# StarFive VisionFive 2 v1.3b register map
File version: 0.1
Registers are 32-bit, read-write, no defined reset value unless marked. A register's access mark holds for its fields unless they carry their own. Offsets are from the block's base; [hi:lo] are bit positions; {n}, {i} and the like mark numbered series.

## starfive_jh7110_sys_pinctrl_0 (part 1 of 3) — From starfive,jh7110-sys-pinctrl, peripheral generator
Base 0x13040000
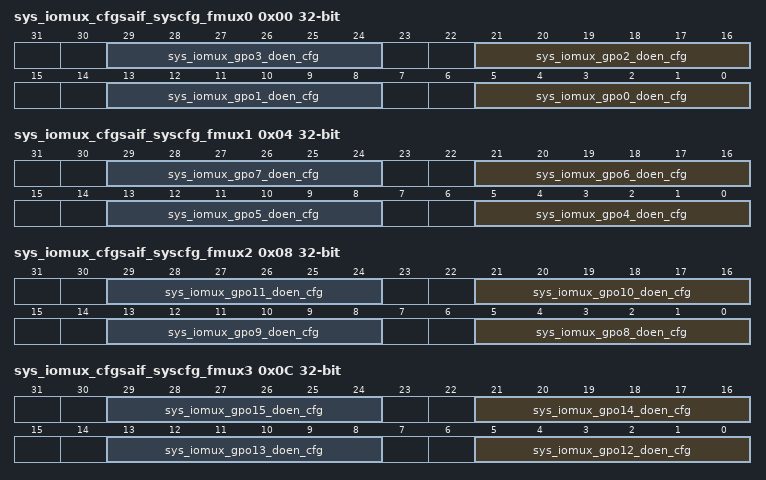
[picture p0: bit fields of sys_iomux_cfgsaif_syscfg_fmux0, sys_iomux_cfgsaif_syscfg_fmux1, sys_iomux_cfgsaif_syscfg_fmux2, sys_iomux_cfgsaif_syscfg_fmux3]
0x00 sys_iomux_cfgsaif_syscfg_fmux0
  [8n+5:8n] sys_iomux_gpo{n}_doen_cfg (n=0..3) — The selected OEN signal for GPIO{n}. The register value indicates the selected GPIO (Output Enable) OEN index from GPIO OEN list 0-49. See Table 2-41: GPIO OEN List for SYS_IOMUX (on page 97) for more information.
0x04 sys_iomux_cfgsaif_syscfg_fmux1
  [8n-27:8n-32] sys_iomux_gpo{n}_doen_cfg (n=4..7) — The selected OEN signal for GPIO{n}. The register value indicates the selected GPIO (Output Enable) OEN index from GPIO OEN list 0-49. See Table 2-41: GPIO OEN List for SYS_IOMUX (on page 97) for more information.
0x08 sys_iomux_cfgsaif_syscfg_fmux2
  [8n-59:8n-64] sys_iomux_gpo{n}_doen_cfg (n=8..11) — The selected OEN signal for GPIO{n}. The register value indicates the selected GPIO (Output Enable) OEN index from GPIO OEN list 0-49. See Table 2-41: GPIO OEN List for SYS_IOMUX (on page 97) for more information.
0x0C sys_iomux_cfgsaif_syscfg_fmux3
  [8n-91:8n-96] sys_iomux_gpo{n}_doen_cfg (n=12..15) — The selected OEN signal for GPIO{n}. The register value indicates the selected GPIO (Output Enable) OEN index from GPIO OEN list 0-49. See Table 2-41: GPIO OEN List for SYS_IOMUX (on page 97) for more information.
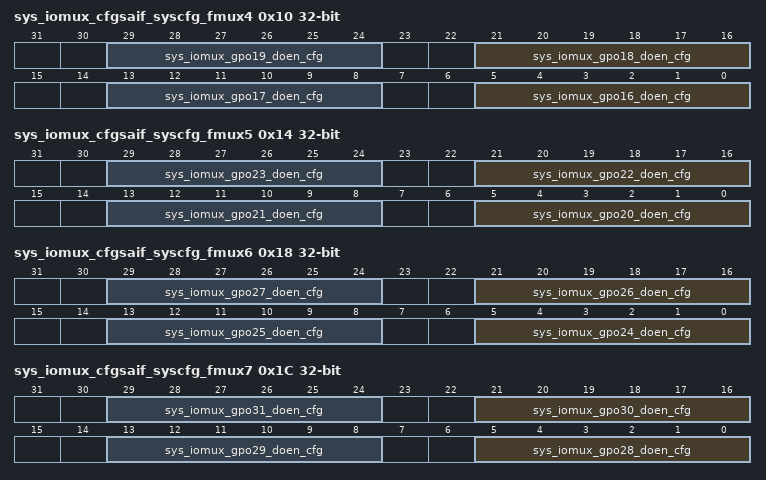
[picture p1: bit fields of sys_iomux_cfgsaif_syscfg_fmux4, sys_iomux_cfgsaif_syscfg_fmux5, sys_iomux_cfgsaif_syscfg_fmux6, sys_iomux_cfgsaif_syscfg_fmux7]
0x10 sys_iomux_cfgsaif_syscfg_fmux4
  [8n-123:8n-128] sys_iomux_gpo{n}_doen_cfg (n=16..19) — The selected OEN signal for GPIO{n}. The register value indicates the selected GPIO (Output Enable) OEN index from GPIO OEN list 0-49. See Table 2-41: GPIO OEN List for SYS_IOMUX (on page 97) for more information.
0x14 sys_iomux_cfgsaif_syscfg_fmux5
  [8n-155:8n-160] sys_iomux_gpo{n}_doen_cfg (n=20..23) — The selected OEN signal for GPIO{n}. The register value indicates the selected GPIO (Output Enable) OEN index from GPIO OEN list 0-49. See Table 2-41: GPIO OEN List for SYS_IOMUX (on page 97) for more information.
0x18 sys_iomux_cfgsaif_syscfg_fmux6
  [8n-187:8n-192] sys_iomux_gpo{n}_doen_cfg (n=24..27) — The selected OEN signal for GPIO{n}. The register value indicates the selected GPIO (Output Enable) OEN index from GPIO OEN list 0-49. See Table 2-41: GPIO OEN List for SYS_IOMUX (on page 97) for more information.
0x1C sys_iomux_cfgsaif_syscfg_fmux7
  [8n-219:8n-224] sys_iomux_gpo{n}_doen_cfg (n=28..31) — The selected OEN signal for GPIO{n}. The register value indicates the selected GPIO (Output Enable) OEN index from GPIO OEN list 0-49. See Table 2-41: GPIO OEN List for SYS_IOMUX (on page 97) for more information.
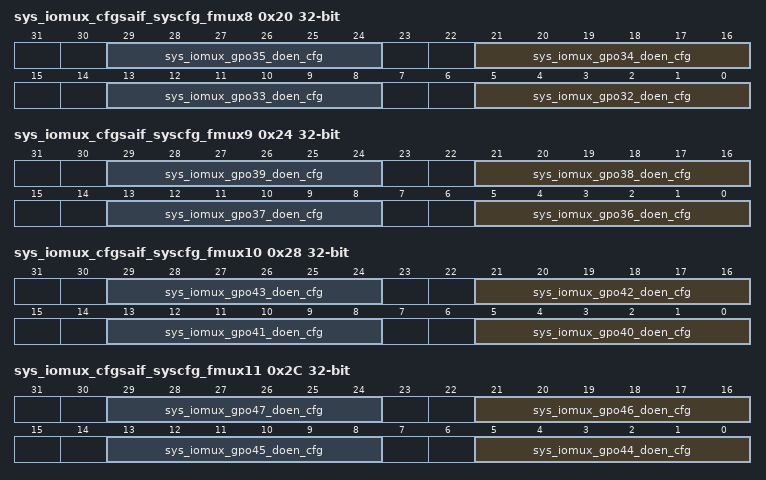
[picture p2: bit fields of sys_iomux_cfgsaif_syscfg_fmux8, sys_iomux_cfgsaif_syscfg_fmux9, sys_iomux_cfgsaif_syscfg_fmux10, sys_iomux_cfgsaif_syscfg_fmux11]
0x20 sys_iomux_cfgsaif_syscfg_fmux8
  [8n-251:8n-256] sys_iomux_gpo{n}_doen_cfg (n=32..35) — The selected OEN signal for GPIO{n}. The register value indicates the selected GPIO (Output Enable) OEN index from GPIO OEN list 0-49. See Table 2-41: GPIO OEN List for SYS_IOMUX (on page 97) for more information.
0x24 sys_iomux_cfgsaif_syscfg_fmux9
  [8n-283:8n-288] sys_iomux_gpo{n}_doen_cfg (n=36..39) — The selected OEN signal for GPIO{n}. The register value indicates the selected GPIO (Output Enable) OEN index from GPIO OEN list 0-49. See Table 2-41: GPIO OEN List for SYS_IOMUX (on page 97) for more information.
0x28 sys_iomux_cfgsaif_syscfg_fmux10
  [8n-315:8n-320] sys_iomux_gpo{n}_doen_cfg (n=40..43) — The selected OEN signal for GPIO{n}. The register value indicates the selected GPIO (Output Enable) OEN index from GPIO OEN list 0-49. See Table 2-41: GPIO OEN List for SYS_IOMUX (on page 97) for more information.
0x2C sys_iomux_cfgsaif_syscfg_fmux11
  [8n-347:8n-352] sys_iomux_gpo{n}_doen_cfg (n=44..47) — The selected OEN signal for GPIO{n}. The register value indicates the selected GPIO (Output Enable) OEN index from GPIO OEN list 0-49. See Table 2-41: GPIO OEN List for SYS_IOMUX (on page 97) for more information.
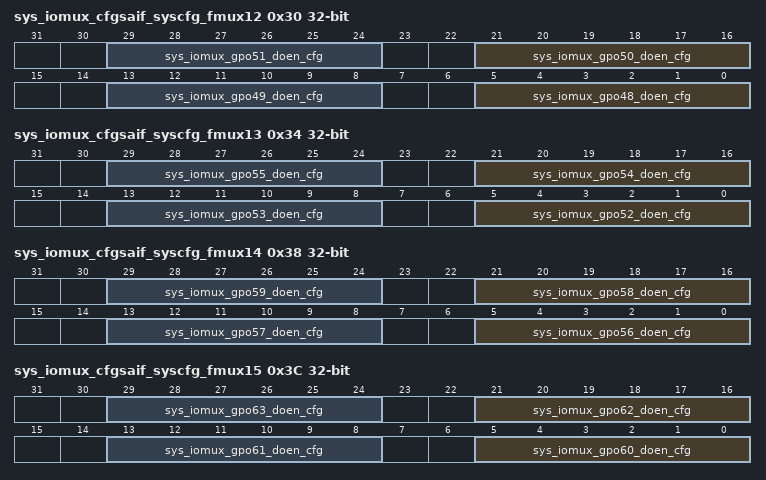
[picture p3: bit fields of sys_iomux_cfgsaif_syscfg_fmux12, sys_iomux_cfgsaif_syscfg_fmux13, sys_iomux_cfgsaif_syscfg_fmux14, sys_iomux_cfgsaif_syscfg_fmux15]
0x30 sys_iomux_cfgsaif_syscfg_fmux12
  [8n-379:8n-384] sys_iomux_gpo{n}_doen_cfg (n=48..51) — The selected OEN signal for GPIO{n}. The register value indicates the selected GPIO (Output Enable) OEN index from GPIO OEN list 0-49. See Table 2-41: GPIO OEN List for SYS_IOMUX (on page 97) for more information.
0x34 sys_iomux_cfgsaif_syscfg_fmux13
  [8n-411:8n-416] sys_iomux_gpo{n}_doen_cfg (n=52..55) — The selected OEN signal for GPIO{n}. The register value indicates the selected GPIO (Output Enable) OEN index from GPIO OEN list 0-49. See Table 2-41: GPIO OEN List for SYS_IOMUX (on page 97) for more information.
0x38 sys_iomux_cfgsaif_syscfg_fmux14
  [8n-443:8n-448] sys_iomux_gpo{n}_doen_cfg (n=56..59) — The selected OEN signal for GPIO{n}. The register value indicates the selected GPIO (Output Enable) OEN index from GPIO OEN list 0-49. See Table 2-41: GPIO OEN List for SYS_IOMUX (on page 97) for more information.
0x3C sys_iomux_cfgsaif_syscfg_fmux15
  [8n-475:8n-480] sys_iomux_gpo{n}_doen_cfg (n=60..63) — The selected OEN signal for GPIO{n}. The register value indicates the selected GPIO (Output Enable) OEN index from GPIO OEN list 0-49. See Table 2-41: GPIO OEN List for SYS_IOMUX (on page 97) for more information.
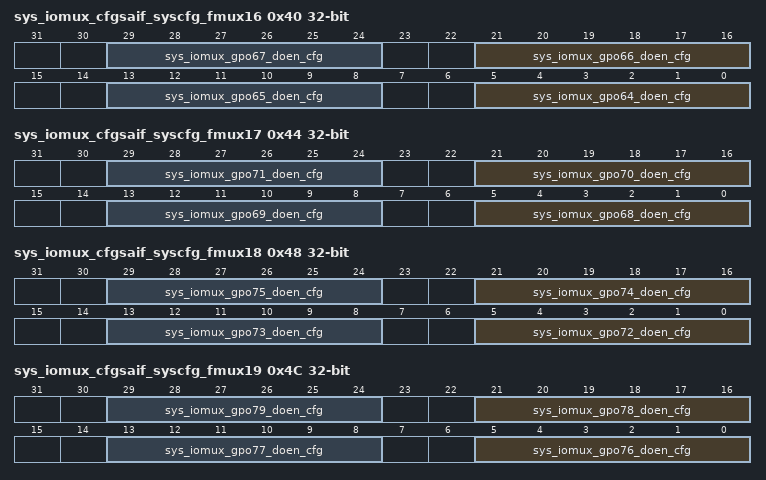
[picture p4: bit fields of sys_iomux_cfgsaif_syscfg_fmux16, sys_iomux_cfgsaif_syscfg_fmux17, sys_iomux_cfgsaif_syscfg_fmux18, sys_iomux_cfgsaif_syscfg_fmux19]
0x40 sys_iomux_cfgsaif_syscfg_fmux16
  [8n-507:8n-512] sys_iomux_gpo{n}_doen_cfg (n=64..67) — The selected OEN signal for GPIO{n}. The register value indicates the selected GPIO (Output Enable) OEN index from GPIO OEN list 0-49. See Table 2-41: GPIO OEN List for SYS_IOMUX (on page 97) for more information.
0x44 sys_iomux_cfgsaif_syscfg_fmux17
  [8n-539:8n-544] sys_iomux_gpo{n}_doen_cfg (n=68..71) — The selected OEN signal for GPIO{n}. The register value indicates the selected GPIO (Output Enable) OEN index from GPIO OEN list 0-49. See Table 2-41: GPIO OEN List for SYS_IOMUX (on page 97) for more information.
0x48 sys_iomux_cfgsaif_syscfg_fmux18
  [8n-571:8n-576] sys_iomux_gpo{n}_doen_cfg (n=72..75) — The selected OEN signal for GPIO{n}. The register value indicates the selected GPIO (Output Enable) OEN index from GPIO OEN list 0-49. See Table 2-41: GPIO OEN List for SYS_IOMUX (on page 97) for more information.
0x4C sys_iomux_cfgsaif_syscfg_fmux19
  [8n-603:8n-608] sys_iomux_gpo{n}_doen_cfg (n=76..79) — The selected OEN signal for GPIO{n}. The register value indicates the selected GPIO (Output Enable) OEN index from GPIO OEN list 0-49. See Table 2-41: GPIO OEN List for SYS_IOMUX (on page 97) for more information.
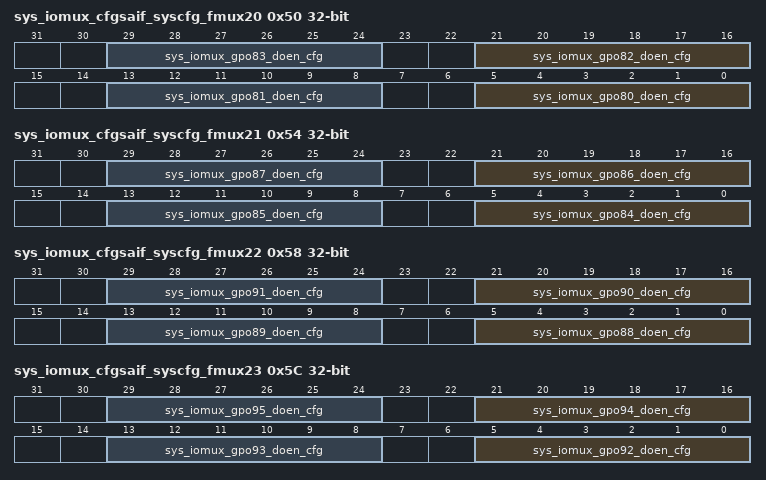
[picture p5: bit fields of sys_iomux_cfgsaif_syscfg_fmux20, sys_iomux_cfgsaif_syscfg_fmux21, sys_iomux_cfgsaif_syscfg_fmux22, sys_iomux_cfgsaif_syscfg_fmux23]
0x50 sys_iomux_cfgsaif_syscfg_fmux20
  [8n-635:8n-640] sys_iomux_gpo{n}_doen_cfg (n=80..83) — The selected OEN signal for GPIO{n}. The register value indicates the selected GPIO (Output Enable) OEN index from GPIO OEN list 0-49. See Table 2-41: GPIO OEN List for SYS_IOMUX (on page 97) for more information.
0x54 sys_iomux_cfgsaif_syscfg_fmux21
  [8n-667:8n-672] sys_iomux_gpo{n}_doen_cfg (n=84..87) — The selected OEN signal for GPIO{n}. The register value indicates the selected GPIO (Output Enable) OEN index from GPIO OEN list 0-49. See Table 2-41: GPIO OEN List for SYS_IOMUX (on page 97) for more information.
0x58 sys_iomux_cfgsaif_syscfg_fmux22
  [8n-699:8n-704] sys_iomux_gpo{n}_doen_cfg (n=88..91) — The selected OEN signal for GPIO{n}. The register value indicates the selected GPIO (Output Enable) OEN index from GPIO OEN list 0-49. See Table 2-41: GPIO OEN List for SYS_IOMUX (on page 97) for more information.
0x5C sys_iomux_cfgsaif_syscfg_fmux23
  [8n-731:8n-736] sys_iomux_gpo{n}_doen_cfg (n=92..95) — The selected OEN signal for GPIO{n}. The register value indicates the selected GPIO (Output Enable) OEN index from GPIO OEN list 0-49. See Table 2-41: GPIO OEN List for SYS_IOMUX (on page 97) for more information.
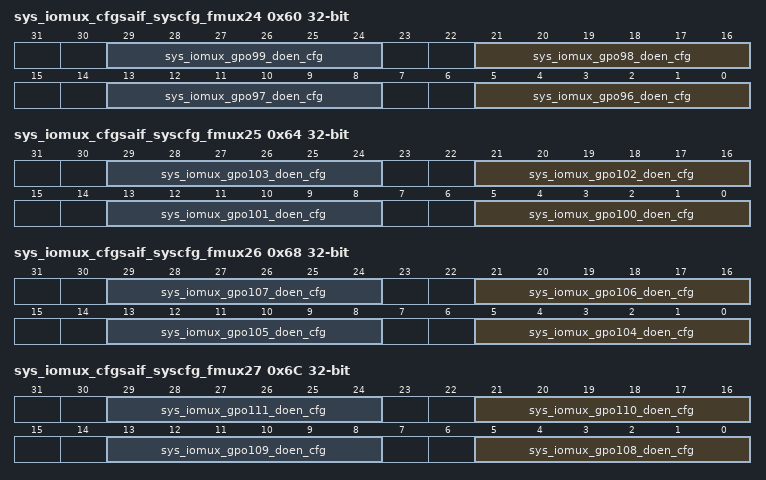
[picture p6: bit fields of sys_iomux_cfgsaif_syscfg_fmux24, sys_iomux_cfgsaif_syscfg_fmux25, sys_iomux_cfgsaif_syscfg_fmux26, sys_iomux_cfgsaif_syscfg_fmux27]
0x60 sys_iomux_cfgsaif_syscfg_fmux24
  [8n-763:8n-768] sys_iomux_gpo{n}_doen_cfg (n=96..99) — The selected OEN signal for GPIO{n}. The register value indicates the selected GPIO (Output Enable) OEN index from GPIO OEN list 0-49. See Table 2-41: GPIO OEN List for SYS_IOMUX (on page 97) for more information.
0x64 sys_iomux_cfgsaif_syscfg_fmux25
  [8n-795:8n-800] sys_iomux_gpo{n}_doen_cfg (n=100..103) — The selected OEN signal for GPIO{n}. The register value indicates the selected GPIO (Output Enable) OEN index from GPIO OEN list 0-49. See Table 2-41: GPIO OEN List for SYS_IOMUX (on page 97) for more information.
0x68 sys_iomux_cfgsaif_syscfg_fmux26
  [8n-827:8n-832] sys_iomux_gpo{n}_doen_cfg (n=104..107) — The selected OEN signal for GPIO{n}. The register value indicates the selected GPIO (Output Enable) OEN index from GPIO OEN list 0-49. See Table 2-41: GPIO OEN List for SYS_IOMUX (on page 97) for more information.
0x6C sys_iomux_cfgsaif_syscfg_fmux27
  [8n-859:8n-864] sys_iomux_gpo{n}_doen_cfg (n=108..111) — The selected OEN signal for GPIO{n}. The register value indicates the selected GPIO (Output Enable) OEN index from GPIO OEN list 0-49. See Table 2-41: GPIO OEN List for SYS_IOMUX (on page 97) for more information.
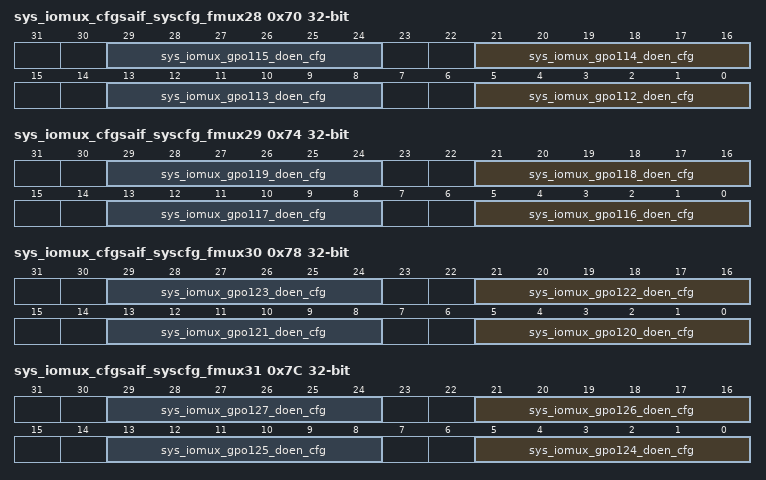
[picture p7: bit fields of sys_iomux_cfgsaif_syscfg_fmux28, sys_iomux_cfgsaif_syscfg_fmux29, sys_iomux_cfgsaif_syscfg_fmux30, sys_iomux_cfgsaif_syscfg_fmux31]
0x70 sys_iomux_cfgsaif_syscfg_fmux28
  [8n-891:8n-896] sys_iomux_gpo{n}_doen_cfg (n=112..115) — The selected OEN signal for GPIO{n}. The register value indicates the selected GPIO (Output Enable) OEN index from GPIO OEN list 0-49. See Table 2-41: GPIO OEN List for SYS_IOMUX (on page 97) for more information.
0x74 sys_iomux_cfgsaif_syscfg_fmux29
  [8n-923:8n-928] sys_iomux_gpo{n}_doen_cfg (n=116..119) — The selected OEN signal for GPIO{n}. The register value indicates the selected GPIO (Output Enable) OEN index from GPIO OEN list 0-49. See Table 2-41: GPIO OEN List for SYS_IOMUX (on page 97) for more information.
0x78 sys_iomux_cfgsaif_syscfg_fmux30
  [8n-955:8n-960] sys_iomux_gpo{n}_doen_cfg (n=120..123) — The selected OEN signal for GPIO{n}. The register value indicates the selected GPIO (Output Enable) OEN index from GPIO OEN list 0-49. See Table 2-41: GPIO OEN List for SYS_IOMUX (on page 97) for more information.
0x7C sys_iomux_cfgsaif_syscfg_fmux31
  [8n-987:8n-992] sys_iomux_gpo{n}_doen_cfg (n=124..127) — The selected OEN signal for GPIO{n}. The register value indicates the selected GPIO (Output Enable) OEN index from GPIO OEN list 0-49. See Table 2-41: GPIO OEN List for SYS_IOMUX (on page 97) for more information.
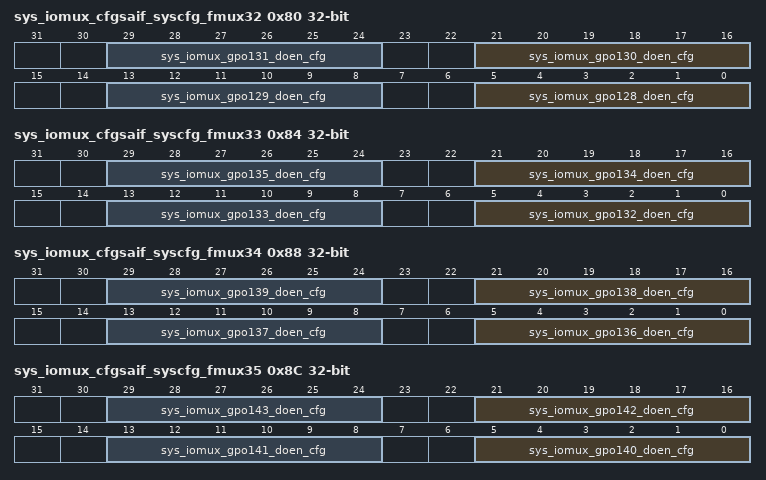
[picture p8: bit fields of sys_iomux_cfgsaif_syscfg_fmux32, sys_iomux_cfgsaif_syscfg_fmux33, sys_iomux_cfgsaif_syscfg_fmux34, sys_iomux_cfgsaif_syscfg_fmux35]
0x80 sys_iomux_cfgsaif_syscfg_fmux32
  [8n-1019:8n-1024] sys_iomux_gpo{n}_doen_cfg (n=128..131) — The selected OEN signal for GPIO{n}. The register value indicates the selected GPIO (Output Enable) OEN index from GPIO OEN list 0-49. See Table 2-41: GPIO OEN List for SYS_IOMUX (on page 97) for more information.
0x84 sys_iomux_cfgsaif_syscfg_fmux33
  [8n-1051:8n-1056] sys_iomux_gpo{n}_doen_cfg (n=132..135) — The selected OEN signal for GPIO{n}. The register value indicates the selected GPIO (Output Enable) OEN index from GPIO OEN list 0-49. See Table 2-41: GPIO OEN List for SYS_IOMUX (on page 97) for more information.
0x88 sys_iomux_cfgsaif_syscfg_fmux34
  [8n-1083:8n-1088] sys_iomux_gpo{n}_doen_cfg (n=136..139) — The selected OEN signal for GPIO{n}. The register value indicates the selected GPIO (Output Enable) OEN index from GPIO OEN list 0-49. See Table 2-41: GPIO OEN List for SYS_IOMUX (on page 97) for more information.
0x8C sys_iomux_cfgsaif_syscfg_fmux35
  [8n-1115:8n-1120] sys_iomux_gpo{n}_doen_cfg (n=140..143) — The selected OEN signal for GPIO{n}. The register value indicates the selected GPIO (Output Enable) OEN index from GPIO OEN list 0-49. See Table 2-41: GPIO OEN List for SYS_IOMUX (on page 97) for more information.
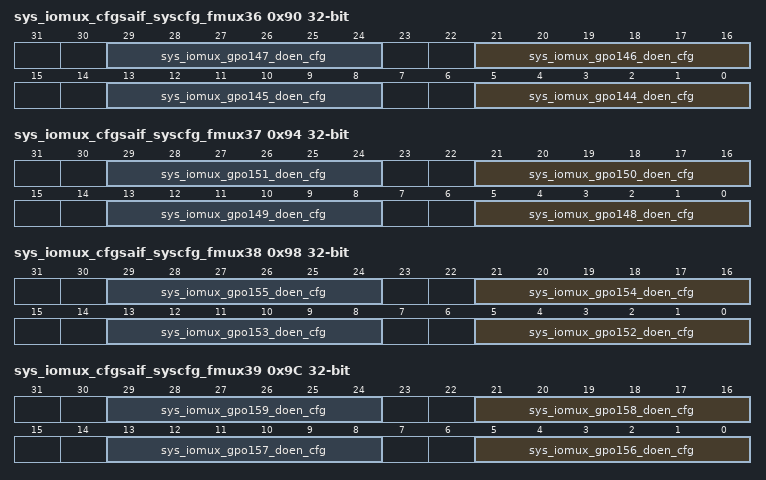
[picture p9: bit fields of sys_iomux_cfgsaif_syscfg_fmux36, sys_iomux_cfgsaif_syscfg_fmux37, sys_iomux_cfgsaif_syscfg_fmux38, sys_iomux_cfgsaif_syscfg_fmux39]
0x90 sys_iomux_cfgsaif_syscfg_fmux36
  [8n-1147:8n-1152] sys_iomux_gpo{n}_doen_cfg (n=144..147) — The selected OEN signal for GPIO{n}. The register value indicates the selected GPIO (Output Enable) OEN index from GPIO OEN list 0-49. See Table 2-41: GPIO OEN List for SYS_IOMUX (on page 97) for more information.
0x94 sys_iomux_cfgsaif_syscfg_fmux37
  [8n-1179:8n-1184] sys_iomux_gpo{n}_doen_cfg (n=148..151) — The selected OEN signal for GPIO{n}. The register value indicates the selected GPIO (Output Enable) OEN index from GPIO OEN list 0-49. See Table 2-41: GPIO OEN List for SYS_IOMUX (on page 97) for more information.
0x98 sys_iomux_cfgsaif_syscfg_fmux38
  [8n-1211:8n-1216] sys_iomux_gpo{n}_doen_cfg (n=152..155) — The selected OEN signal for GPIO{n}. The register value indicates the selected GPIO (Output Enable) OEN index from GPIO OEN list 0-49. See Table 2-41: GPIO OEN List for SYS_IOMUX (on page 97) for more information.
0x9C sys_iomux_cfgsaif_syscfg_fmux39
  [8n-1243:8n-1248] sys_iomux_gpo{n}_doen_cfg (n=156..159) — The selected OEN signal for GPIO{n}. The register value indicates the selected GPIO (Output Enable) OEN index from GPIO OEN list 0-49. See Table 2-41: GPIO OEN List for SYS_IOMUX (on page 97) for more information.
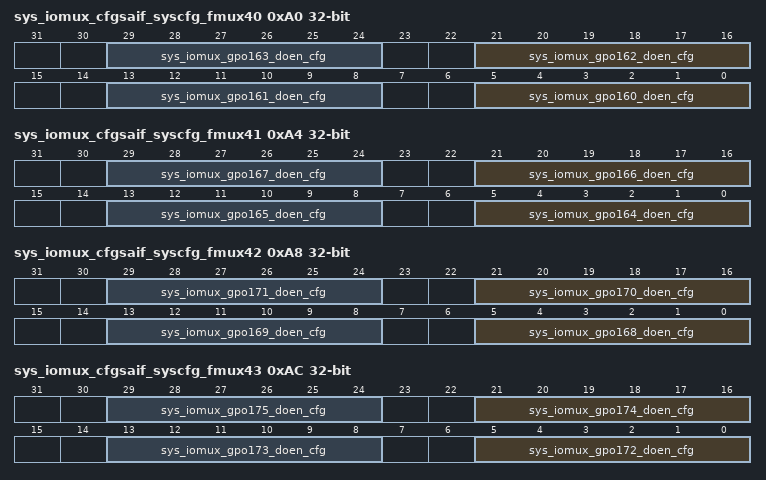
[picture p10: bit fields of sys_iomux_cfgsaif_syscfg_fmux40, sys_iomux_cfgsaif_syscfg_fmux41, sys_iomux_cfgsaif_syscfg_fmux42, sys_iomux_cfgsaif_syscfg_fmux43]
0xA0 sys_iomux_cfgsaif_syscfg_fmux40
  [8n-1275:8n-1280] sys_iomux_gpo{n}_doen_cfg (n=160..163) — The selected OEN signal for GPIO{n}. The register value indicates the selected GPIO (Output Enable) OEN index from GPIO OEN list 0-49. See Table 2-41: GPIO OEN List for SYS_IOMUX (on page 97) for more information.
0xA4 sys_iomux_cfgsaif_syscfg_fmux41
  [8n-1307:8n-1312] sys_iomux_gpo{n}_doen_cfg (n=164..167) — The selected OEN signal for GPIO{n}. The register value indicates the selected GPIO (Output Enable) OEN index from GPIO OEN list 0-49. See Table 2-41: GPIO OEN List for SYS_IOMUX (on page 97) for more information.
0xA8 sys_iomux_cfgsaif_syscfg_fmux42
  [8n-1339:8n-1344] sys_iomux_gpo{n}_doen_cfg (n=168..171) — The selected OEN signal for GPIO{n}. The register value indicates the selected GPIO (Output Enable) OEN index from GPIO OEN list 0-49. See Table 2-41: GPIO OEN List for SYS_IOMUX (on page 97) for more information.
0xAC sys_iomux_cfgsaif_syscfg_fmux43
  [8n-1371:8n-1376] sys_iomux_gpo{n}_doen_cfg (n=172..175) — The selected OEN signal for GPIO{n}. The register value indicates the selected GPIO (Output Enable) OEN index from GPIO OEN list 0-49. See Table 2-41: GPIO OEN List for SYS_IOMUX (on page 97) for more information.
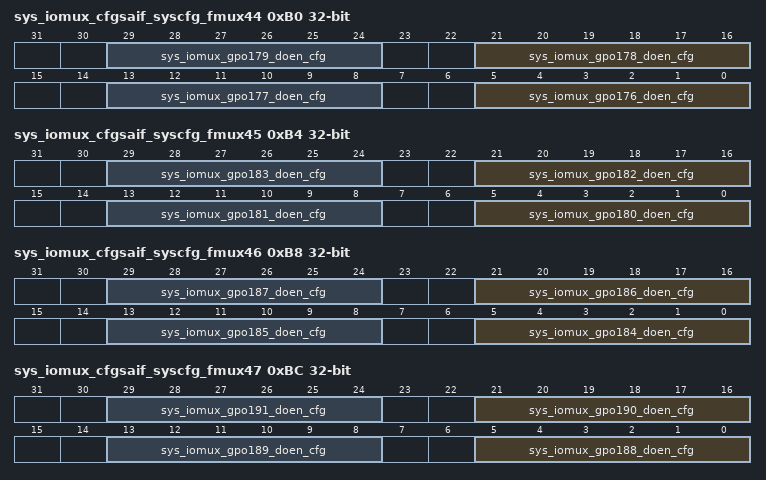
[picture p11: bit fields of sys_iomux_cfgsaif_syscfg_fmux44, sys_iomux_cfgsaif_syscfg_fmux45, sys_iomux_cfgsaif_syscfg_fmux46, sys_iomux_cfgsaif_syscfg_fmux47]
0xB0 sys_iomux_cfgsaif_syscfg_fmux44
  [8n-1403:8n-1408] sys_iomux_gpo{n}_doen_cfg (n=176..179) — The selected OEN signal for GPIO{n}. The register value indicates the selected GPIO (Output Enable) OEN index from GPIO OEN list 0-49. See Table 2-41: GPIO OEN List for SYS_IOMUX (on page 97) for more information.
0xB4 sys_iomux_cfgsaif_syscfg_fmux45
  [8n-1435:8n-1440] sys_iomux_gpo{n}_doen_cfg (n=180..183) — The selected OEN signal for GPIO{n}. The register value indicates the selected GPIO (Output Enable) OEN index from GPIO OEN list 0-49. See Table 2-41: GPIO OEN List for SYS_IOMUX (on page 97) for more information.
0xB8 sys_iomux_cfgsaif_syscfg_fmux46
  [8n-1467:8n-1472] sys_iomux_gpo{n}_doen_cfg (n=184..187) — The selected OEN signal for GPIO{n}. The register value indicates the selected GPIO (Output Enable) OEN index from GPIO OEN list 0-49. See Table 2-41: GPIO OEN List for SYS_IOMUX (on page 97) for more information.
0xBC sys_iomux_cfgsaif_syscfg_fmux47
  [8n-1499:8n-1504] sys_iomux_gpo{n}_doen_cfg (n=188..191) — The selected OEN signal for GPIO{n}. The register value indicates the selected GPIO (Output Enable) OEN index from GPIO OEN list 0-49. See Table 2-41: GPIO OEN List for SYS_IOMUX (on page 97) for more information.
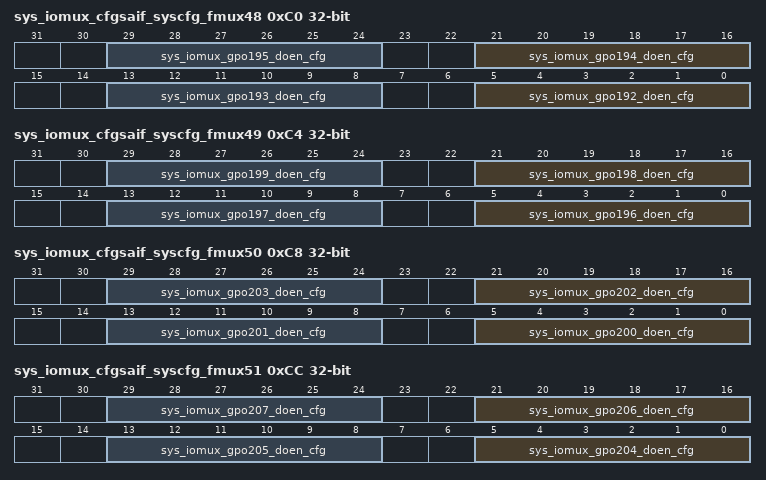
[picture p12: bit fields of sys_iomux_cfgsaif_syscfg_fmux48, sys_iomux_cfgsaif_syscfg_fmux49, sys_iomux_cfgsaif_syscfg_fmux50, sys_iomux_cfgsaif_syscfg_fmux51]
0xC0 sys_iomux_cfgsaif_syscfg_fmux48
  [8n-1531:8n-1536] sys_iomux_gpo{n}_doen_cfg (n=192..195) — The selected OEN signal for GPIO{n}. The register value indicates the selected GPIO (Output Enable) OEN index from GPIO OEN list 0-49. See Table 2-41: GPIO OEN List for SYS_IOMUX (on page 97) for more information.
0xC4 sys_iomux_cfgsaif_syscfg_fmux49
  [8n-1563:8n-1568] sys_iomux_gpo{n}_doen_cfg (n=196..199) — The selected OEN signal for GPIO{n}. The register value indicates the selected GPIO (Output Enable) OEN index from GPIO OEN list 0-49. See Table 2-41: GPIO OEN List for SYS_IOMUX (on page 97) for more information.
0xC8 sys_iomux_cfgsaif_syscfg_fmux50
  [8n-1595:8n-1600] sys_iomux_gpo{n}_doen_cfg (n=200..203) — The selected OEN signal for GPIO{n}. The register value indicates the selected GPIO (Output Enable) OEN index from GPIO OEN list 0-49. See Table 2-41: GPIO OEN List for SYS_IOMUX (on page 97) for more information.
0xCC sys_iomux_cfgsaif_syscfg_fmux51
  [8n-1627:8n-1632] sys_iomux_gpo{n}_doen_cfg (n=204..207) — The selected OEN signal for GPIO{n}. The register value indicates the selected GPIO (Output Enable) OEN index from GPIO OEN list 0-49. See Table 2-41: GPIO OEN List for SYS_IOMUX (on page 97) for more information.
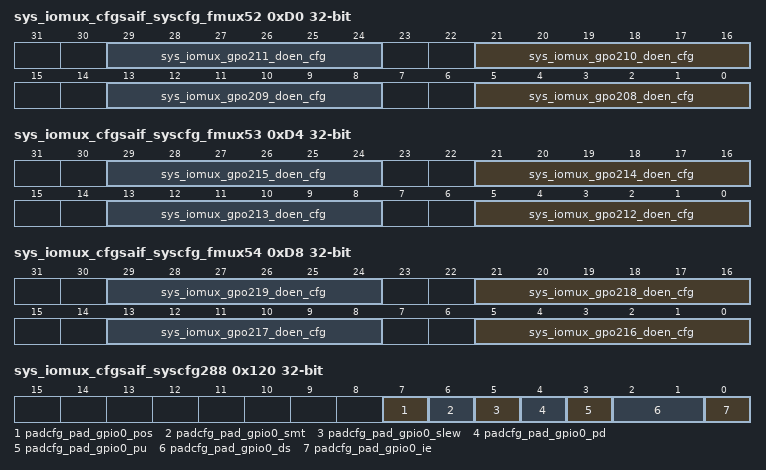
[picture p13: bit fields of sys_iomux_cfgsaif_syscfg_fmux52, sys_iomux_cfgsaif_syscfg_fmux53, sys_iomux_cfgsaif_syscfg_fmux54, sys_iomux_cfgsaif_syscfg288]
0xD0 sys_iomux_cfgsaif_syscfg_fmux52
  [8n-1659:8n-1664] sys_iomux_gpo{n}_doen_cfg (n=208..211) — The selected OEN signal for GPIO{n}. The register value indicates the selected GPIO (Output Enable) OEN index from GPIO OEN list 0-49. See Table 2-41: GPIO OEN List for SYS_IOMUX (on page 97) for more information.
0xD4 sys_iomux_cfgsaif_syscfg_fmux53
  [8n-1691:8n-1696] sys_iomux_gpo{n}_doen_cfg (n=212..215) — The selected OEN signal for GPIO{n}. The register value indicates the selected GPIO (Output Enable) OEN index from GPIO OEN list 0-49. See Table 2-41: GPIO OEN List for SYS_IOMUX (on page 97) for more information.
0xD8 sys_iomux_cfgsaif_syscfg_fmux54
  [8n-1723:8n-1728] sys_iomux_gpo{n}_doen_cfg (n=216..219) — The selected OEN signal for GPIO{n}. The register value indicates the selected GPIO (Output Enable) OEN index from GPIO OEN list 0-49. See Table 2-41: GPIO OEN List for SYS_IOMUX (on page 97) for more information.
0xDC sys_iomux_cfgsaif_syscfg_ioirq55
  [0] sys_gpioen_0_reg — Enable GPIO IRQ function
0xE0 sys_iomux_cfgsaif_syscfg_ioirq56
  [31:0] sys_gpiois_0_reg — 1: Edge trigger, 0: Level trigger
0xE4 sys_iomux_cfgsaif_syscfg_ioirq57
  [31:0] sys_gpiois_1_reg — 1: Edge trigger, 0: Level trigger
0xE8 sys_iomux_cfgsaif_syscfg_ioirq58
  [31:0] sys_gpioic_0_reg — 1: Do not clear the register, 0: Clear the register
0xEC sys_iomux_cfgsaif_syscfg_ioirq59
  [31:0] sys_gpioic_1_reg — 1: Do not clear the register, 0: Clear the register
0xF0 sys_iomux_cfgsaif_syscfg_ioirq60
  [31:0] sys_gpioibe_0_reg — 1: Trigger on both edges, 0: Trigger on a single edge
0xF4 sys_iomux_cfgsaif_syscfg_ioirq61
  [31:0] sys_gpioibe_1_reg — 1: Trigger on both edges, 0: Trigger on a single edge
0xF8 sys_iomux_cfgsaif_syscfg_ioirq62
  [31:0] sys_gpioiev_0_reg — 1: Positive/Low, 0: Negative/High
0xFC sys_iomux_cfgsaif_syscfg_ioirq63
  [31:0] sys_gpioiev_1_reg — 1: Positive/Low, 0: Negative/High
0x100 sys_iomux_cfgsaif_syscfg_ioirq64
  [31:0] sys_gpioie_0_reg — 1: Unmask, 0: Mask
0x104 sys_iomux_cfgsaif_syscfg_ioirq65
  [31:0] sys_gpioie_1_reg — 1: Unmask, 0: Mask
0x108 sys_iomux_cfgsaif_syscfg_ioirq66
  [31:0] sys_gpioris_0_reg ro — Status of the edge trigger. The register can be cleared by writing gpio ic
0x10C sys_iomux_cfgsaif_syscfg_ioirq67
  [31:0] sys_gpioris_1_reg ro — Status of the edge trigger. The register can be cleared by writing gpio ic
0x110 sys_iomux_cfgsaif_syscfg_ioirq68
  [31:0] sys_gpiomis_0_reg ro — The masked GPIO IRQ status
0x114 sys_iomux_cfgsaif_syscfg_ioirq69
  [31:0] sys_gpiomis_1_reg ro — The masked GPIO IRQ status
0x118 sys_iomux_cfgsaif_syscfg_ioirq70
  [31:0] sys_gpio_in_sync2_0_reg ro — Status of the gpio_in after synchronization
0x11C sys_iomux_cfgsaif_syscfg_ioirq71
  [31:0] sys_gpio_in_sync2_1_reg ro — Status of the gpio_in after synchronization
0x120 sys_iomux_cfgsaif_syscfg288
  [7] padcfg_pad_gpio0_pos — Power-on-Start (POS) enabler - 1: Enable active pull down for loss of core power, 0: Active pull-down capability disabled
  [6] padcfg_pad_gpio0_smt — Active high Schmitt (SMT) trigger selector - 0: No hysteresis, 1: Schmitt trigger ebabled
  [5] padcfg_pad_gpio0_slew — Slew Rate Control - 0: Slow (Half frequency), 1: Fast
  [4] padcfg_pad_gpio0_pd — Pull-Down (PD) settings - 1: Yes, 0: No
  [3] padcfg_pad_gpio0_pu — Pull-Up (PU) settings - 1: Yes, 0: No
  [2:1] padcfg_pad_gpio0_ds — Output Drive Strength (DS) - 00: The rated drive strength is 2 mA, 01: The rated drive strength is 4 mA, 10: The rated drive strength is 8 mA, 11: The rated drive strength is 12 mA
  [0] padcfg_pad_gpio0_ie — Input Enable (IE) Controller - 1: Enable the receiver, 0: Disable the receiver
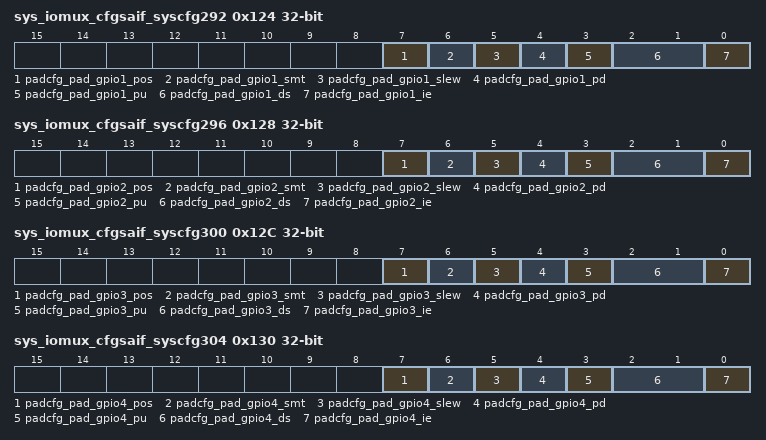
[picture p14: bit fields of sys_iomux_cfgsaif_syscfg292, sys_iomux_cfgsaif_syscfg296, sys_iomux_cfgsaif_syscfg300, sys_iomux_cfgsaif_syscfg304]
0x124 sys_iomux_cfgsaif_syscfg292
  [7] padcfg_pad_gpio1_pos — Power-on-Start (POS) enabler - 1: Enable active pull down for loss of core power, 0: Active pull-down capability disabled
  [6] padcfg_pad_gpio1_smt — Active high Schmitt (SMT) trigger selector - 0: No hysteresis, 1: Schmitt trigger ebabled
  [5] padcfg_pad_gpio1_slew — Slew Rate Control - 0: Slow (Half frequency), 1: Fast
  [4] padcfg_pad_gpio1_pd — Pull-Down (PD) settings - 1: Yes, 0: No
  [3] padcfg_pad_gpio1_pu — Pull-Up (PU) settings - 1: Yes, 0: No
  [2:1] padcfg_pad_gpio1_ds — Output Drive Strength (DS) - 00: The rated drive strength is 2 mA, 01: The rated drive strength is 4 mA, 10: The rated drive strength is 8 mA, 11: The rated drive strength is 12 mA
  [0] padcfg_pad_gpio1_ie — Input Enable (IE) Controller - 1: Enable the receiver, 0: Disable the receiver
0x128 sys_iomux_cfgsaif_syscfg296
  [7] padcfg_pad_gpio2_pos — Power-on-Start (POS) enabler - 1: Enable active pull down for loss of core power, 0: Active pull-down capability disabled
  [6] padcfg_pad_gpio2_smt — Active high Schmitt (SMT) trigger selector - 0: No hysteresis, 1: Schmitt trigger ebabled
  [5] padcfg_pad_gpio2_slew — Slew Rate Control - 0: Slow (Half frequency), 1: Fast
  [4] padcfg_pad_gpio2_pd — Pull-Down (PD) settings - 1: Yes, 0: No
  [3] padcfg_pad_gpio2_pu — Pull-Up (PU) settings - 1: Yes, 0: No
  [2:1] padcfg_pad_gpio2_ds — Output Drive Strength (DS) - 00: The rated drive strength is 2 mA, 01: The rated drive strength is 4 mA, 10: The rated drive strength is 8 mA, 11: The rated drive strength is 12 mA
  [0] padcfg_pad_gpio2_ie — Input Enable (IE) Controller - 1: Enable the receiver, 0: Disable the receiver
0x12C sys_iomux_cfgsaif_syscfg300
  [7] padcfg_pad_gpio3_pos — Power-on-Start (POS) enabler - 1: Enable active pull down for loss of core power, 0: Active pull-down capability disabled
  [6] padcfg_pad_gpio3_smt — Active high Schmitt (SMT) trigger selector - 0: No hysteresis, 1: Schmitt trigger ebabled
  [5] padcfg_pad_gpio3_slew — Slew Rate Control - 0: Slow (Half frequency), 1: Fast
  [4] padcfg_pad_gpio3_pd — Pull-Down (PD) settings - 1: Yes, 0: No
  [3] padcfg_pad_gpio3_pu — Pull-Up (PU) settings - 1: Yes, 0: No
  [2:1] padcfg_pad_gpio3_ds — Output Drive Strength (DS) - 00: The rated drive strength is 2 mA, 01: The rated drive strength is 4 mA, 10: The rated drive strength is 8 mA, 11: The rated drive strength is 12 mA
  [0] padcfg_pad_gpio3_ie — Input Enable (IE) Controller - 1: Enable the receiver, 0: Disable the receiver
0x130 sys_iomux_cfgsaif_syscfg304
  [7] padcfg_pad_gpio4_pos — Power-on-Start (POS) enabler - 1: Enable active pull down for loss of core power, 0: Active pull-down capability disabled
  [6] padcfg_pad_gpio4_smt — Active high Schmitt (SMT) trigger selector - 0: No hysteresis, 1: Schmitt trigger ebabled
  [5] padcfg_pad_gpio4_slew — Slew Rate Control - 0: Slow (Half frequency), 1: Fast
  [4] padcfg_pad_gpio4_pd — Pull-Down (PD) settings - 1: Yes, 0: No
  [3] padcfg_pad_gpio4_pu — Pull-Up (PU) settings - 1: Yes, 0: No
  [2:1] padcfg_pad_gpio4_ds — Output Drive Strength (DS) - 00: The rated drive strength is 2 mA, 01: The rated drive strength is 4 mA, 10: The rated drive strength is 8 mA, 11: The rated drive strength is 12 mA
  [0] padcfg_pad_gpio4_ie — Input Enable (IE) Controller - 1: Enable the receiver, 0: Disable the receiver
0x134 sys_iomux_cfgsaif_syscfg308
  [7] padcfg_pad_gpio5_pos — Power-on-Start (POS) enabler - 1: Enable active pull down for loss of core power, 0: Active pull-down capability disabled
  [6] padcfg_pad_gpio5_smt — Active high Schmitt (SMT) trigger selector - 0: No hysteresis, 1: Schmitt trigger ebabled
  [5] padcfg_pad_gpio5_slew — Slew Rate Control - 0: Slow (Half frequency), 1: Fast
  [4] padcfg_pad_gpio5_pd — Pull-Down (PD) settings - 1: Yes, 0: No
  [3] padcfg_pad_gpio5_pu — Pull-Up (PU) settings - 1: Yes, 0: No
  [2:1] padcfg_pad_gpio5_ds — Output Drive Strength (DS) - 00: The rated drive strength is 2 mA, 01: The rated drive strength is 4 mA, 10: The rated drive strength is 8 mA, 11: The rated drive strength is 12 mA
  [0] padcfg_pad_gpio5_ie — Input Enable (IE) Controller - 1: Enable the receiver, 0: Disable the receiver
0x138 sys_iomux_cfgsaif_syscfg312
  [7] padcfg_pad_gpio6_pos — Power-on-Start (POS) enabler - 1: Enable active pull down for loss of core power, 0: Active pull-down capability disabled
  [6] padcfg_pad_gpio6_smt — Active high Schmitt (SMT) trigger selector - 0: No hysteresis, 1: Schmitt trigger ebabled
  [5] padcfg_pad_gpio6_slew — Slew Rate Control - 0: Slow (Half frequency), 1: Fast
  [4] padcfg_pad_gpio6_pd — Pull-Down (PD) settings - 1: Yes, 0: No
  [3] padcfg_pad_gpio6_pu — Pull-Up (PU) settings - 1: Yes, 0: No
  [2:1] padcfg_pad_gpio6_ds — Output Drive Strength (DS) - 00: The rated drive strength is 2 mA, 01: The rated drive strength is 4 mA, 10: The rated drive strength is 8 mA, 11: The rated drive strength is 12 mA
  [0] padcfg_pad_gpio6_ie — Input Enable (IE) Controller - 1: Enable the receiver, 0: Disable the receiver
0x13C sys_iomux_cfgsaif_syscfg316
  [7] padcfg_pad_gpio7_pos — Power-on-Start (POS) enabler - 1: Enable active pull down for loss of core power, 0: Active pull-down capability disabled
  [6] padcfg_pad_gpio7_smt — Active high Schmitt (SMT) trigger selector - 0: No hysteresis, 1: Schmitt trigger ebabled
  [5] padcfg_pad_gpio7_slew — Slew Rate Control - 0: Slow (Half frequency), 1: Fast
  [4] padcfg_pad_gpio7_pd — Pull-Down (PD) settings - 1: Yes, 0: No
  [3] padcfg_pad_gpio7_pu — Pull-Up (PU) settings - 1: Yes, 0: No
  [2:1] padcfg_pad_gpio7_ds — Output Drive Strength (DS) - 00: The rated drive strength is 2 mA, 01: The rated drive strength is 4 mA, 10: The rated drive strength is 8 mA, 11: The rated drive strength is 12 mA
  [0] padcfg_pad_gpio7_ie — Input Enable (IE) Controller - 1: Enable the receiver, 0: Disable the receiver
0x140 sys_iomux_cfgsaif_syscfg320
  [7] padcfg_pad_gpio8_pos — Power-on-Start (POS) enabler - 1: Enable active pull down for loss of core power, 0: Active pull-down capability disabled
  [6] padcfg_pad_gpio8_smt — Active high Schmitt (SMT) trigger selector - 0: No hysteresis, 1: Schmitt trigger ebabled
  [5] padcfg_pad_gpio8_slew — Slew Rate Control - 0: Slow (Half frequency), 1: Fast
  [4] padcfg_pad_gpio8_pd — Pull-Down (PD) settings - 1: Yes, 0: No
  [3] padcfg_pad_gpio8_pu — Pull-Up (PU) settings - 1: Yes, 0: No
  [2:1] padcfg_pad_gpio8_ds — Output Drive Strength (DS) - 00: The rated drive strength is 2 mA, 01: The rated drive strength is 4 mA, 10: The rated drive strength is 8 mA, 11: The rated drive strength is 12 mA
  [0] padcfg_pad_gpio8_ie — Input Enable (IE) Controller - 1: Enable the receiver, 0: Disable the receiver
0x144 sys_iomux_cfgsaif_syscfg324
  [7] padcfg_pad_gpio9_pos — Power-on-Start (POS) enabler - 1: Enable active pull down for loss of core power, 0: Active pull-down capability disabled
  [6] padcfg_pad_gpio9_smt — Active high Schmitt (SMT) trigger selector - 0: No hysteresis, 1: Schmitt trigger ebabled
  [5] padcfg_pad_gpio9_slew — Slew Rate Control - 0: Slow (Half frequency), 1: Fast
  [4] padcfg_pad_gpio9_pd — Pull-Down (PD) settings - 1: Yes, 0: No
  [3] padcfg_pad_gpio9_pu — Pull-Up (PU) settings - 1: Yes, 0: No
  [2:1] padcfg_pad_gpio9_ds — Output Drive Strength (DS) - 00: The rated drive strength is 2 mA, 01: The rated drive strength is 4 mA, 10: The rated drive strength is 8 mA, 11: The rated drive strength is 12 mA
  [0] padcfg_pad_gpio9_ie — Input Enable (IE) Controller - 1: Enable the receiver, 0: Disable the receiver
0x148 sys_iomux_cfgsaif_syscfg328
  [7] padcfg_pad_gpio10_pos — Power-on-Start (POS) enabler - 1: Enable active pull down for loss of core power, 0: Active pull-down capability disabled
  [6] padcfg_pad_gpio10_smt — Active high Schmitt (SMT) trigger selector - 0: No hysteresis, 1: Schmitt trigger ebabled
  [5] padcfg_pad_gpio10_slew — Slew Rate Control - 0: Slow (Half frequency), 1: Fast
  [4] padcfg_pad_gpio10_pd — Pull-Down (PD) settings - 1: Yes, 0: No
  [3] padcfg_pad_gpio10_pu — Pull-Up (PU) settings - 1: Yes, 0: No
  [2:1] padcfg_pad_gpio10_ds — Output Drive Strength (DS) - 00: The rated drive strength is 2 mA, 01: The rated drive strength is 4 mA, 10: The rated drive strength is 8 mA, 11: The rated drive strength is 12 mA
  [0] padcfg_pad_gpio10_ie — Input Enable (IE) Controller - 1: Enable the receiver, 0: Disable the receiver
0x14C sys_iomux_cfgsaif_syscfg332
  [7] padcfg_pad_gpio11_pos — Power-on-Start (POS) enabler - 1: Enable active pull down for loss of core power, 0: Active pull-down capability disabled
  [6] padcfg_pad_gpio11_smt — Active high Schmitt (SMT) trigger selector - 0: No hysteresis, 1: Schmitt trigger ebabled
  [5] padcfg_pad_gpio11_slew — Slew Rate Control - 0: Slow (Half frequency), 1: Fast
  [4] padcfg_pad_gpio11_pd — Pull-Down (PD) settings - 1: Yes, 0: No
  [3] padcfg_pad_gpio11_pu — Pull-Up (PU) settings - 1: Yes, 0: No
  [2:1] padcfg_pad_gpio11_ds — Output Drive Strength (DS) - 00: The rated drive strength is 2 mA, 01: The rated drive strength is 4 mA, 10: The rated drive strength is 8 mA, 11: The rated drive strength is 12 mA
  [0] padcfg_pad_gpio11_ie — Input Enable (IE) Controller - 1: Enable the receiver, 0: Disable the receiver
0x150 sys_iomux_cfgsaif_syscfg336
  [7] padcfg_pad_gpio12_pos — Power-on-Start (POS) enabler - 1: Enable active pull down for loss of core power, 0: Active pull-down capability disabled
  [6] padcfg_pad_gpio12_smt — Active high Schmitt (SMT) trigger selector - 0: No hysteresis, 1: Schmitt trigger ebabled
  [5] padcfg_pad_gpio12_slew — Slew Rate Control - 0: Slow (Half frequency), 1: Fast
  [4] padcfg_pad_gpio12_pd — Pull-Down (PD) settings - 1: Yes, 0: No
  [3] padcfg_pad_gpio12_pu — Pull-Up (PU) settings - 1: Yes, 0: No
  [2:1] padcfg_pad_gpio12_ds — Output Drive Strength (DS) - 00: The rated drive strength is 2 mA, 01: The rated drive strength is 4 mA, 10: The rated drive strength is 8 mA, 11: The rated drive strength is 12 mA
  [0] padcfg_pad_gpio12_ie — Input Enable (IE) Controller - 1: Enable the receiver, 0: Disable the receiver
0x154 sys_iomux_cfgsaif_syscfg340
  [7] padcfg_pad_gpio13_pos — Power-on-Start (POS) enabler - 1: Enable active pull down for loss of core power, 0: Active pull-down capability disabled
  [6] padcfg_pad_gpio13_smt — Active high Schmitt (SMT) trigger selector - 0: No hysteresis, 1: Schmitt trigger ebabled
  [5] padcfg_pad_gpio13_slew — Slew Rate Control - 0: Slow (Half frequency), 1: Fast
  [4] padcfg_pad_gpio13_pd — Pull-Down (PD) settings - 1: Yes, 0: No
  [3] padcfg_pad_gpio13_pu — Pull-Up (PU) settings - 1: Yes, 0: No
  [2:1] padcfg_pad_gpio13_ds — Output Drive Strength (DS) - 00: The rated drive strength is 2 mA, 01: The rated drive strength is 4 mA, 10: The rated drive strength is 8 mA, 11: The rated drive strength is 12 mA
  [0] padcfg_pad_gpio13_ie — Input Enable (IE) Controller - 1: Enable the receiver, 0: Disable the receiver
0x158 sys_iomux_cfgsaif_syscfg344
  [7] padcfg_pad_gpio14_pos — Power-on-Start (POS) enabler - 1: Enable active pull down for loss of core power, 0: Active pull-down capability disabled
  [6] padcfg_pad_gpio14_smt — Active high Schmitt (SMT) trigger selector - 0: No hysteresis, 1: Schmitt trigger ebabled
  [5] padcfg_pad_gpio14_slew — Slew Rate Control - 0: Slow (Half frequency), 1: Fast
  [4] padcfg_pad_gpio14_pd — Pull-Down (PD) settings - 1: Yes, 0: No
  [3] padcfg_pad_gpio14_pu — Pull-Up (PU) settings - 1: Yes, 0: No
  [2:1] padcfg_pad_gpio14_ds — Output Drive Strength (DS) - 00: The rated drive strength is 2 mA, 01: The rated drive strength is 4 mA, 10: The rated drive strength is 8 mA, 11: The rated drive strength is 12 mA
  [0] padcfg_pad_gpio14_ie — Input Enable (IE) Controller - 1: Enable the receiver, 0: Disable the receiver
